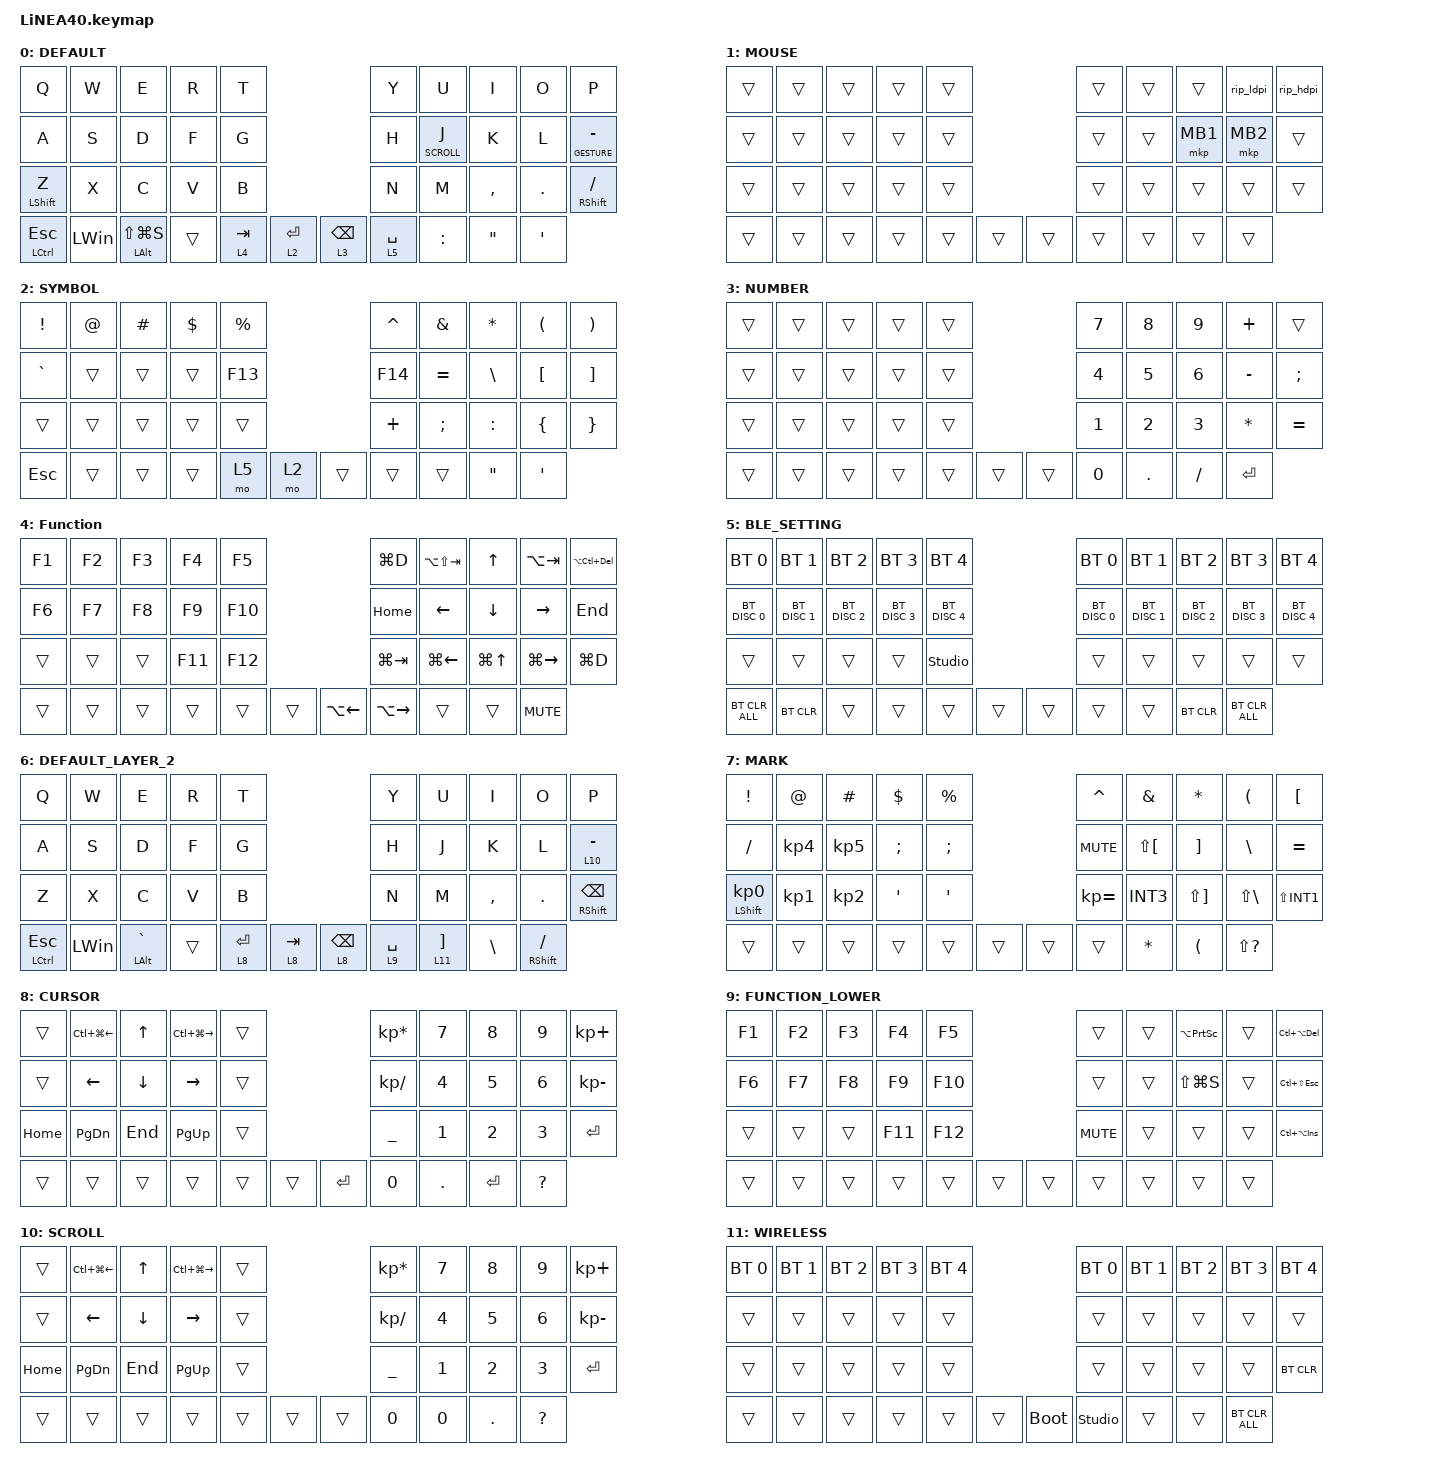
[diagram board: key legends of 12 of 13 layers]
#define ZMK_POINTING_DEFAULT_SCRL_VAL 100

#include <dt-bindings/zmk/input_transform.h>
#include <input/processors.dtsi>
#include <input/processors/runtime-input-processor.dtsi> //DYA Studio対応のため追加(20260405)
#include <behaviors/runtime-input-processor.dtsi> //DPI一時変更(&rip_ldpi/&rip_hdpi)用
#include <zephyr/dt-bindings/input/input-event-codes.h>
#include <behaviors.dtsi>
#include <dt-bindings/zmk/bt.h>
#include <dt-bindings/zmk/keys.h>
#include <dt-bindings/zmk/pointing.h>

#define DEFAULT 0
#define MOUSE 1
#define SYMBOL 2
#define NUMBER 3
#define FUNCTION 4
#define BLE_SETTING 5
#define DEFAULT_LAYER_2 6 // 2つ目のデフォルトレイヤー
#define MARK 7
#define CURSOR 8
#define FUNCTION_LOWER 9       // 追加されたFUNCTIONレイヤー
#define SCROLL 10
#define WIRELESS 11
#define GESTURE 12     // "-"長押し中だけ有効。ボール左右でブラウザの戻る/進む

//mouse cursol
&mmv {
    delay-ms = <20>;
    trigger-period-ms = <20>; //<5>; chatGPTおすすめにより変更
    time-to-max-speed-ms = <300>; //<100>; chatGPTおすすめにより変更
    acceleration-exponent = <1>; //<2>; chatGPTおすすめにより変更
};

//mouse scroll
&msc {
    delay-ms = <3>;//<10>; chatGPTおすすめにより変更
    trigger-period-ms = <3>; //<15>; chatGPTおすすめにより変更
    time-to-max-speed-ms = <100>; //<300>; chatGPTおすすめにより変更
    acceleration-exponent = <0>; //<1>; chatGPTおすすめにより変更
};

/ {
    input_processors {
        zip_wheel_scaler: zip_wheel_scaler {
            compatible = "zmk,input-processor-scaler";
            #input-processor-cells = <2>;
            type = <INPUT_EV_REL>;
            codes = <INPUT_REL_WHEEL>;
            track-remainders;
        };

        // 自作プロセッサ(リポジトリ直下 src/input_processor_gesture_nav.c)。
        // ボールの横移動を積算し、threshold を超えたら1回だけ発火する。
        //   左 → MB4(ブラウザの戻る) / 右 → MB5(進む)
        // MB4/MB5は標準のマウスボタンなので、PC側にソフト不要(Edge/Chrome共通)。
        zip_gesture_nav: zip_gesture_nav {
            compatible = "zmk,input-processor-gesture-nav";
            #input-processor-cells = <0>;
            bindings = <&mkp MB4>, <&mkp MB5>;
            threshold = <150>;      // 反応に必要な振り幅。小さいほど敏感
            cooldown-ms = <400>;    // 1回振って複数回戻らないための間隔
        };
    };
};

&msc_input_listener {
    // ここは左手エンコーダのスクロール経路。
    // 以前は <&scroll_runtime_input_processor> を通していたが外した。理由:
    //  ・トラックボールのスクロールはPMW3610ドライバ側で処理しており、この経路は通らない。
    //    そのためDYA Studioで"scroll"の倍率をいじってもトラックボールには効かず、
    //    エンコーダだけが遅く(または動かなく)なってしまう。
    //  ・外すことでエンコーダ側はフラッシュに保存された設定の影響を受けなくなり、
    //    DYA導入前と同じ挙動(ZMK_POINTING_DEFAULT_SCRL_VAL がそのまま効く)に戻る。
    // 左手側の速度を変えたいときはファイル冒頭の ZMK_POINTING_DEFAULT_SCRL_VAL を調整する。

    speed_up {
        layers = <FUNCTION>;
        input-processors = <&zip_wheel_scaler 3 1>; //スクロールを3倍速にする
    };
};

// DPI一時変更ビヘイビア(モジュール既定は 0.5x / 1.5x)。
// 「もう少し」の変化量にしたいので 2/3 倍・3/2 倍に調整。
// 数値を変えれば効き具合を変えられる(分子=scale-multiplier, 分母=scale-divisor)。
&rip_ldpi {
    scale-multiplier = <2>;
    scale-divisor = <3>;    // 約0.67倍(遅く)
};

&rip_hdpi {
    scale-multiplier = <3>;
    scale-divisor = <2>;    // 1.5倍(速く)
};

&trackball_listener {
    // ここはoverlayより後に適用されるため、このinput-processorsがoverlay側の指定を
    // 完全に置き換える。zip_temp_layerを書き忘れるとオートマウスレイヤーが働かず、
    // MOUSEレイヤー上の&mkp MB1/MB2(左右クリック)が押せなくなるので必ず両方書く。
    input-processors =
        <&zip_temp_layer MOUSE 10000>,       //トラボ使用後10秒間MOUSEレイヤーが有効
        <&mouse_runtime_input_processor>;    //DYA Studio対応のため追加(20260405)

    // scroller(input-processorでXY→スクロール変換する経路)は廃止した。
    // SCROLLレイヤーのスクロールは overlay の scroll-layers = <5 10> により
    // PMW3610ドライバ側で行う(SPACE長押しのスクロールと同じ仕組みに統一)。
    // ここを残すとレイヤー10で二重に変換が走り、かつ scroll_runtime_input_processor は
    // エンコーダ(&msc_input_listener)と倍率を共有しているため速度がおかしくなる。

    // "-"長押し(GESTUREレイヤー)中は、上の通常処理の代わりにジェスチャ判定だけを通す。
    // process-next を付けていないので zip_temp_layer やカーソル移動は走らない。
    gesture {
        layers = <GESTURE>;
        input-processors = <&zip_gesture_nav>;
    };
};

/ {
    combos {
        compatible = "zmk,combos";

        //        ZenkakuHankaku {
        //            bindings = <&kp GRAVE>;
        //            key-positions = <11 12>;
        //        };

        DeleteKey {
            bindings = <&kp DEL>;
            key-positions = <7 8>;
        };

        //        InsertKey {
        //            bindings = <&kp INS>;
        //            key-positions = <6 7>;
        //        };
        //        CenterClick {
        //            bindings = <&mkp MB3>;
        //            key-positions = <17 16>;
        //        };
        //        RightClick {
        //            bindings = <&mkp MB2>;
        //            key-positions = <18 17>;
        //        };

        PrevClick {
            bindings = <&mkp MB4>;
            key-positions = <27 28>;
        };

        ClickNext {
            bindings = <&mkp MB5>;
            key-positions = <26 27>;
        };
    };

    behaviors {
        re_kp: sensor_rotate_kp {
            compatible = "zmk,behavior-sensor-rotate-var";
            #sensor-binding-cells = <2>;
            bindings = <&kp>, <&kp>;
        };

        mouse_scrl: mouse_wheel_scrl {
            compatible = "zmk,behavior-sensor-rotate-var";
            #sensor-binding-cells = <2>;
            bindings = <&msc>, <&msc>;

            tap-ms = <20>;
        };

        // 標準の &lt に quick-tap-ms を足したもの。Enter / BackSpace / Space に使用。
        // 「1回叩いて、すぐもう一度押しっぱなし」にするとタップ側のキーが押されっぱなしになり、
        // OSのキーリピートが効く。単独の長押しは従来どおりレイヤー切替。
        //
        // quick-tap-ms = 2回目を押すまでの猶予。他のホールドタップの待機時間
        //                (tapping-term-ms) と同じ200msに揃えてある。長くすると
        //                ゆっくり押し直しても連打になるが、その分誤爆しやすい。
        // ※リピート開始までの待ち時間と連打速度は「キーを押しっぱなしにしている」
        //   状態をOSが解釈して決めるので、他のキーと自動的に同じになる(ZMK側では制御しない)。
        lt_rpt: layer_tap_repeat {
            compatible = "zmk,behavior-hold-tap";
            #binding-cells = <2>;
            flavor = "tap-preferred";
            tapping-term-ms = <200>;
            quick-tap-ms = <200>;
            bindings = <&mo>, <&kp>;

            display-name = "Layer-Tap (repeat)";
        };
    };

    macros {
        Ime_tog: Ime_tog {
            compatible = "zmk,behavior-macro";
            #binding-cells = <0>;
            bindings =
                <&macro_press>,
                <&kp LALT>,
                <&macro_tap>,
                <&kp GRAVE>,
                <&macro_release>,
                <&kp LALT>;

            label = "IME_TOG";
        };
    };

    keymap {
        compatible = "zmk,keymap";

        DEFAULT {
            bindings = <
&kp Q             &kp W         &kp E                   &kp R   &kp T                                      &kp Y        &kp U  &kp I      &kp O              &kp P
&kp A             &kp S         &kp D                   &kp F   &kp G                                      &kp H        &lt SCROLL J  &kp K  &kp L          &lt GESTURE MINUS
&mt LEFT_SHIFT Z  &kp X         &kp C                   &kp V   &kp B                                      &kp N        &kp M  &kp COMMA  &kp PERIOD         &mt RIGHT_SHIFT SLASH
&mt LCTRL ESC     &kp LEFT_WIN  &mt LEFT_ALT LS(LG(S))  &trans  &lt 4 TAB  &lt_rpt 2 ENTER    &lt_rpt 3 BACKSPACE  &lt_rpt 5 SPACE     &kp COLON  &kp DOUBLE_QUOTES  &kp SINGLE_QUOTE
            >;

            sensor-bindings = <&mouse_scrl SCRL_DOWN SCRL_UP>;
        };

        MOUSE {
            bindings = <
&trans  &trans  &trans  &trans  &trans                    &trans  &trans  &trans    &rip_ldpi  &rip_hdpi
&trans  &trans  &trans  &trans  &trans                    &trans  &trans  &mkp MB1  &mkp MB2  &trans
&trans  &trans  &trans  &trans  &trans                    &trans  &trans  &trans    &trans    &trans
&trans  &trans  &trans  &trans  &trans  &trans    &trans  &trans          &trans    &trans    &trans
            >;

            sensor-bindings = <&mouse_scrl SCRL_DOWN SCRL_UP>;
        };

        SYMBOL {
            bindings = <
&kp EXCLAMATION  &kp AT_SIGN  &kp HASH  &kp DOLLAR  &kp PERCENT                   &kp CARET  &kp AMPERSAND  &kp ASTERISK   &kp LEFT_PARENTHESIS  &kp RIGHT_PARENTHESIS
&kp GRAVE        &trans       &trans    &trans      &kp F13                       &kp F14    &kp EQUAL      &kp BACKSLASH  &kp LEFT_BRACKET      &kp RIGHT_BRACKET
&trans           &trans       &trans    &trans      &trans                        &kp PLUS   &kp SEMICOLON  &kp COLON      &kp LEFT_BRACE        &kp RIGHT_BRACE
&kp ESC          &trans       &trans    &trans      &mo 5        &mo 2    &trans  &trans                    &trans         &kp DOUBLE_QUOTES     &kp SINGLE_QUOTE
            >;

            sensor-bindings = <&mouse_scrl SCRL_RIGHT SCRL_LEFT>;
        };

        NUMBER {
            bindings = <
&trans  &trans  &trans  &trans  &trans                    &kp N7  &kp N8  &kp N9   &kp PLUS      &trans
&trans  &trans  &trans  &trans  &trans                    &kp N4  &kp N5  &kp N6   &kp MINUS     &kp SEMICOLON
&trans  &trans  &trans  &trans  &trans                    &kp N1  &kp N2  &kp N3   &kp ASTERISK  &kp EQUAL
&trans  &trans  &trans  &trans  &trans  &trans    &trans  &kp N0          &kp DOT  &kp FSLH      &kp ENTER
            >;

            sensor-bindings = <&mouse_scrl SCRL_RIGHT SCRL_LEFT>;
        };

        Function {
            bindings = <
&kp F1  &kp F2  &kp F3  &kp F4   &kp F5                           &kp LG(D)      &kp LA(LS(TAB))  &kp UP_ARROW  &kp LA(TAB)      &kp LA(LC(DELETE))
&kp F6  &kp F7  &kp F8  &kp F9   &kp F10                          &kp HOME       &kp LEFT_ARROW   &kp DOWN      &kp RIGHT_ARROW  &kp END
&trans  &trans  &trans  &kp F11  &kp F12                          &kp LG(TAB)    &kp LG(LEFT)     &kp LG(UP)    &kp LG(RIGHT)    &kp LG(D)
&trans  &trans  &trans  &trans   &trans   &trans    &kp LA(LEFT)  &kp LA(RIGHT)                   &trans        &trans           &kp C_MUTE
            >;

            sensor-bindings = <&re_kp C_VOLUME_DOWN C_VOLUME_UP>;
        };

        BLE_SETTING {
            bindings = <
&bt BT_SEL 0    &bt BT_SEL 1   &bt BT_SEL 2   &bt BT_SEL 3   &bt BT_SEL 4                     &bt BT_SEL 0   &bt BT_SEL 1   &bt BT_SEL 2   &bt BT_SEL 3   &bt BT_SEL 4
&bt BT_DISC 0   &bt BT_DISC 1  &bt BT_DISC 2  &bt BT_DISC 3  &bt BT_DISC 4                    &bt BT_DISC 0  &bt BT_DISC 1  &bt BT_DISC 2  &bt BT_DISC 3  &bt BT_DISC 4
&trans          &trans         &trans         &trans         &studio_unlock                           &trans         &trans         &trans         &trans         &trans
&bt BT_CLR_ALL  &bt BT_CLR     &trans         &trans         &trans         &trans    &trans  &trans                        &trans         &bt BT_CLR     &bt BT_CLR_ALL
            >;

            sensor-bindings = <&re_kp C_VOLUME_DOWN C_VOLUME_UP>;
        };

        DEFAULT_LAYER_2 {
            bindings = <
&kp Q          &kp W         &kp E               &kp R   &kp T                                      &kp Y        &kp U  &kp I                 &kp O          &kp P
&kp A          &kp S         &kp D               &kp F   &kp G                                      &kp H        &kp J  &kp K                 &kp L          &lt 10 MINUS
&kp Z          &kp X         &kp C               &kp V   &kp B                                      &kp N        &kp M  &kp COMMA             &kp DOT        &mt RIGHT_SHIFT BACKSPACE
&mt LCTRL ESC  &kp LEFT_WIN  &mt LEFT_ALT GRAVE  &trans  &lt 8 ENTER  &lt 8 TAB    &lt 8 BACKSPACE  &lt 9 SPACE         &lt 11 RIGHT_BRACKET  &kp BACKSLASH  &mt RIGHT_SHIFT SLASH
            >;

            sensor-bindings = <&mouse_scrl SCRL_DOWN SCRL_UP>;
        };

        MARK {
            bindings = <
&kp EXCLAMATION             &kp AT           &kp HASH         &kp DOLLAR     &kp PERCENT                      &kp CARET     &kp AMPERSAND  &kp ASTERISK           &kp LEFT_PARENTHESIS  &kp LBKT
&kp SLASH                   &kp KP_NUMBER_4  &kp KP_NUMBER_5  &kp SEMICOLON  &kp SEMICOLON                    &kp C_MUTE    &kp LS(LBKT)   &kp RIGHT_BRACKET      &kp BACKSLASH         &kp EQUAL
&mt LEFT_SHIFT KP_NUMBER_0  &kp KP_NUMBER_1  &kp KP_NUMBER_2  &kp APOS       &kp SQT                          &kp KP_EQUAL  &kp INT3       &kp LS(RIGHT_BRACKET)  &kp LS(BACKSLASH)     &kp LS(INT1)
&trans                      &trans           &trans           &trans         &trans         &trans    &trans  &trans                       &kp ASTERISK           &kp LEFT_PARENTHESIS  &kp LS(QUESTION)
            >;

            sensor-bindings = <&re_kp C_VOLUME_DOWN C_VOLUME_UP>;
        };

        CURSOR {
            bindings = <
&trans    &kp LC(LG(LEFT_ARROW))  &kp UP_ARROW  &kp LC(LG(RIGHT_ARROW))  &trans                       &kp KP_MULTIPLY  &kp NUMBER_7  &kp NUMBER_8  &kp NUMBER_9  &kp KP_PLUS
&trans    &kp LEFT_ARROW          &kp DOWN      &kp RIGHT_ARROW          &trans                       &kp KP_SLASH     &kp NUMBER_4  &kp NUMBER_5  &kp NUMBER_6  &kp KP_MINUS
&kp HOME  &kp PAGE_DOWN           &kp END       &kp PAGE_UP              &trans                       &kp UNDER        &kp NUMBER_1  &kp NUMBER_2  &kp NUMBER_3  &kp ENTER
&trans    &trans                  &trans        &trans                   &trans  &trans    &kp ENTER  &kp NUMBER_0                   &kp DOT       &kp ENTER     &kp QUESTION
            >;
        };

        FUNCTION_LOWER {
            bindings = <
&kp F1  &kp F2  &kp F3  &kp F4   &kp F5                     &trans      &trans  &kp LA(PRINTSCREEN)  &trans  &kp LC(LA(DELETE))
&kp F6  &kp F7  &kp F8  &kp F9   &kp F10                    &trans      &trans  &kp LS(LG(S))        &trans  &kp LC(LS(ESCAPE))
&trans  &trans  &trans  &kp F11  &kp F12                    &kp C_MUTE  &trans  &trans               &trans  &kp LC(LA(INS))
&trans  &trans  &trans  &trans   &trans   &trans    &trans  &trans              &trans               &trans  &trans
            >;

            sensor-bindings = <&mouse_scrl SCRL_DOWN SCRL_UP>;
        };

        SCROLL {
            bindings = <
&trans    &kp LC(LG(LEFT_ARROW))  &kp UP_ARROW  &kp LC(LG(RIGHT_ARROW))  &trans                    &kp KP_MULTIPLY  &kp NUMBER_7  &kp NUMBER_8  &kp NUMBER_9  &kp KP_PLUS
&trans    &kp LEFT_ARROW          &kp DOWN      &kp RIGHT_ARROW          &trans                    &kp KP_SLASH     &kp NUMBER_4  &kp NUMBER_5  &kp NUMBER_6  &kp KP_MINUS
&kp HOME  &kp PAGE_DOWN           &kp END       &kp PAGE_UP              &trans                    &kp UNDER        &kp NUMBER_1  &kp NUMBER_2  &kp NUMBER_3  &kp ENTER
&trans    &trans                  &trans        &trans                   &trans  &trans    &trans  &kp NUMBER_0                   &kp NUMBER_0  &kp DOT       &kp QUESTION
            >;

            sensor-bindings = <&inc_dec_kp DOWN_ARROW UP_ARROW>;
        };

        WIRELESS {
            bindings = <
&bt BT_SEL 0  &bt BT_SEL 1  &bt BT_SEL 2  &bt BT_SEL 3  &bt BT_SEL 4                         &bt BT_SEL 0    &bt BT_SEL 1  &bt BT_SEL 2  &bt BT_SEL 3  &bt BT_SEL 4
&trans        &trans        &trans        &trans        &trans                               &trans          &trans        &trans        &trans        &trans
&trans        &trans        &trans        &trans        &trans                               &trans          &trans        &trans        &trans        &bt BT_CLR
&trans        &trans        &trans        &trans        &trans        &trans    &bootloader  &studio_unlock                &trans        &trans        &bt BT_CLR_ALL
            >;

            sensor-bindings = <&inc_dec_kp RIGHT_ARROW LEFT_ARROW>;
        };

        // "-"長押しで有効。キーは全て下のレイヤーのまま(ボールのジェスチャ専用)。
        GESTURE {
            bindings = <
&trans  &trans  &trans  &trans  &trans                    &trans  &trans  &trans  &trans  &trans
&trans  &trans  &trans  &trans  &trans                    &trans  &trans  &trans  &trans  &trans
&trans  &trans  &trans  &trans  &trans                    &trans  &trans  &trans  &trans  &trans
&trans  &trans  &trans  &trans  &trans  &trans    &trans  &trans          &trans  &trans  &trans
            >;
        };
    };
};
